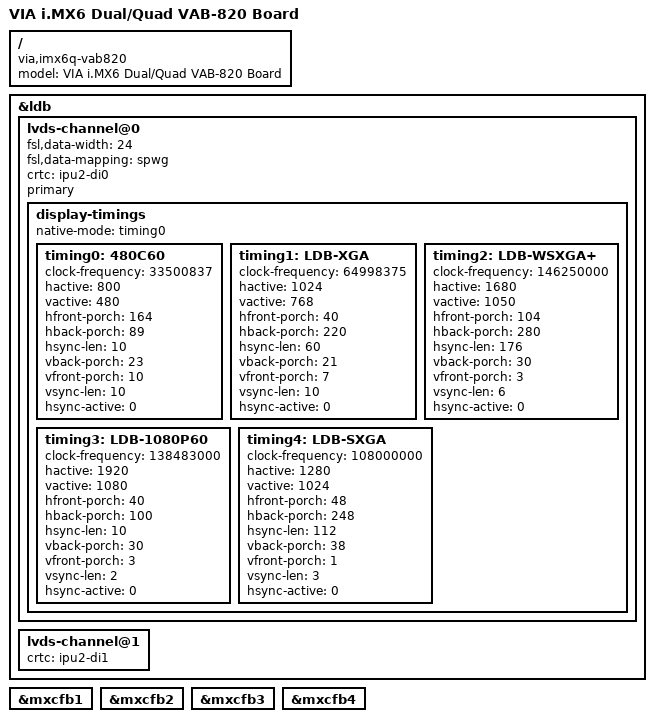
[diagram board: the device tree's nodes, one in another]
/*
 * Copyright 2014-2016 VIA
 * Copyright 2012-2015 Freescale Semiconductor, Inc.
 * Copyright 2011 Linaro Ltd.
 *
 * The code contained herein is licensed under the GNU General Public
 * License. You may obtain a copy of the GNU General Public License
 * Version 2 or later at the following locations:
 *
 * http://www.opensource.org/licenses/gpl-license.html
 * http://www.gnu.org/copyleft/gpl.html
 */

/dts-v1/;

#include "imx6q.dtsi"
#include "imx6qdl-vab820.dtsi"

/ {
	model = "VIA i.MX6 Dual/Quad VAB-820 Board";
	compatible = "via,imx6q-vab820", "fsl,imx6q";
};

&ldb	{
	status = "okay";
	
	lvds-channel@0 {
		fsl,data-width = <24>;
		fsl,data-mapping = "spwg";
		crtc = "ipu2-di0";
		status = "okay";
		primary;
		display-timings {
			native-mode = <&timing0>;

			timing0: 480C60 {
				/* 800x480@60*/
				clock-frequency = <33500837>;
				hactive = <800>;
				vactive = <480>;
				hfront-porch = <164>;
				hback-porch = <89>;
				hsync-len = <10>;
				vback-porch = <23>;
				vfront-porch = <10>;
				vsync-len = <10>;
				hsync-active = <0>;
			};

			timing1: LDB-XGA {
				/* 1024x768@60 */
				clock-frequency = <64998375>;
				hactive = <1024>;
				vactive = <768>;
				hfront-porch = <40>;
				hback-porch = <220>;
				hsync-len = <60>;
				vback-porch = <21>;
				vfront-porch = <7>;
				vsync-len = <10>;
				hsync-active = <0>;
			};

			timing2: LDB-WSXGA+ {
				/* 1680x1050@60 */
				clock-frequency = <146250000>;
				hactive = <1680>;
				vactive = <1050>;
				hfront-porch = <104>;
				hback-porch = <280>;
				hsync-len = <176>;
				vback-porch = <30>;
				vfront-porch = <3>;
				vsync-len = <6>;
				hsync-active = <0>;
			};

			timing3: LDB-1080P60 {
				/* 1920x1080@60 */
				clock-frequency = <138483000>;
				hactive = <1920>;
				vactive = <1080>;
				hfront-porch = <40>;
				hback-porch = <100>;
				hsync-len = <10>;
				vback-porch = <30>;
				vfront-porch = <3>;
				vsync-len = <2>;
				hsync-active = <0>;
			};

			timing4: LDB-SXGA {
				/* 1280x1024@60 */
				clock-frequency = <108000000>;
				hactive = <1280>;
				vactive = <1024>;
				hfront-porch = <48>;
				hback-porch = <248>;
				hsync-len = <112>;
				vback-porch = <38>;
				vfront-porch = <1>;
				vsync-len = <3>;
				hsync-active = <0>;
			};

		};
	};

	lvds-channel@1 {
		crtc = "ipu2-di1";
	};
};

&mxcfb1 {
	status = "okay";
};

&mxcfb2 {
	status = "okay";
};

&mxcfb3 {
	status = "okay";
};

&mxcfb4 {
	status = "okay";
};
